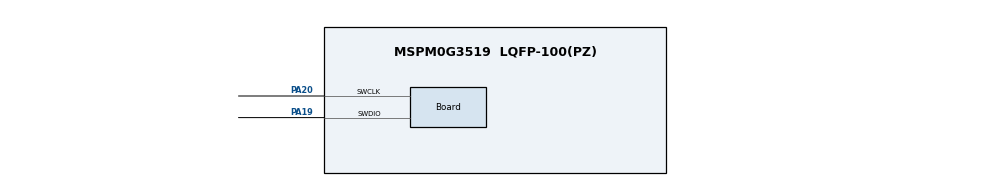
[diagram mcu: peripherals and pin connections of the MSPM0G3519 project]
//@cliArgs --device "MSPM0G351X" --package "LQFP-100(PZ)" --part "Default"
//@v2CliArgs --device "MSPM0G3519" --package "LQFP-100(PZ)"
// @cliArgs --board /ti/boards/LP_MSPM0G3519 --rtos nortos

/**
 * Import the modules used in this configuration.
 */
const Board  = scripting.addModule("/ti/driverlib/Board");
const COMP   = scripting.addModule("/ti/driverlib/COMP", {}, false);
const COMP1  = COMP.addInstance();
const SYSCTL = scripting.addModule("/ti/driverlib/SYSCTL");
const VREF   = scripting.addModule("/ti/driverlib/VREF");

/**
 * Write custom configuration values to the imported modules.
 */
Board.InitPriority8               = "/ti/driverlib/VREF";
Board.peripheral.$assign          = "DEBUGSS";
Board.peripheral.swclkPin.$assign = "PA20";
Board.peripheral.swdioPin.$assign = "PA19";

COMP1.$name                          = "COMP_0";
COMP1.channelEnable                  = ["NEG","POS"];
COMP1.hysteresis                     = "DL_COMP_HYSTERESIS_20";
COMP1.selectOutputFilter             = "DL_COMP_FILTER_DELAY_1200";
COMP1.enableOutputFilter             = true;
COMP1.outputEnable                   = true;
COMP1.peripheral.$assign             = "COMP0";
COMP1.peripheral.compPinPos0.$assign = "PA26";
COMP1.peripheral.compPinNeg0.$assign = "PA27";
COMP1.peripheral.compPinOut.$assign  = "PB10";
COMP1.compPinPos0Config.$name        = "ti_driverlib_gpio_GPIOPinGeneric1";
COMP1.compPinNeg0Config.$name        = "ti_driverlib_gpio_GPIOPinGeneric2";
COMP1.compPinOutConfig.$name         = "ti_driverlib_gpio_GPIOPinGeneric3";

SYSCTL.forceDefaultClkConfig = true;
SYSCTL.clockTreeEn           = true;

VREF.peripheral.$assign            = "VREF";

const ProjectConfig              = scripting.addModule("/ti/project_config/ProjectConfig", {}, false);
ProjectConfig.migrationCondition = true;
